# NANO103AE_v1 register map
File version: 1.0
Registers are 32-bit, read-write, reset 0x0 unless marked. A register's access mark holds for its fields unless they carry their own. Offsets are from the block's base; [hi:lo] are bit positions; {n}, {i} and the like mark numbered series.

## DSRC — DSRC Register Map
Base 0x401F0000
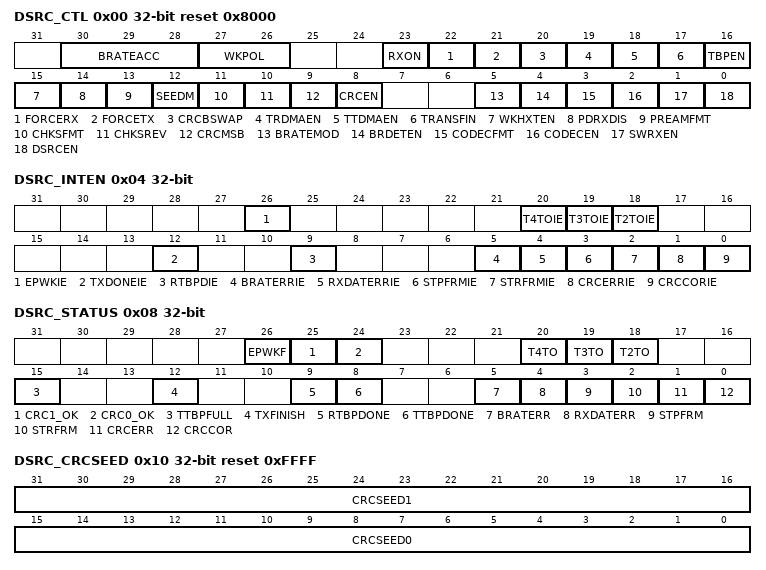
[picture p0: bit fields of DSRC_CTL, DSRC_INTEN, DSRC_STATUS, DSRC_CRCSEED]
0x00 DSRC_CTL reset 0x8000 — DSRC Control Register
  [30:28] BRATEACC — Bit Rate Accuracy Control Bits. Please refer to Table 6.181. Note: This function is only for FM0 CODEC.
  [27:26] WKPOL — Wake-up Pin Polarity Control Bit
    0=Wake-up pin rising edge wake-up DSRC; 1=Wake-up pin falling edge wake-up DSRC
  [23] RXON — RX_ON Control Bit
    0=RX_ON signal Enabled; 1=RX_ON signal Disabled
  [22] FORCERX — Force RX State Control Bit. Note: This bit will be cleared automatically.
    0=No effect; 1=DSRC returns Start_Rx state immediately
  [21] FORCETX — Force TX State Control Bit. Note: This bit will be cleared automatically
    0=No effect; 1=DSRC returns TX state to transmit data immediately
  [20] CRCBSWAP — CRC BYTE SWAP
    0=The received CRC value is not byte swap; 1=The received CRC value is byte swap
  [19] TRDMAEN — TBP Receive DMA Enable Bit
    0=TBP Receiving DMA Disabled; 1=TBP Receiving DMA Enabled
  [18] TTDMAEN — TBP Transmit DMA Enable Bit
    0=TBP Transmitting DMA Disabled; 1=TBP Transmitting DMA Enabled
  [17] TRANSFIN — TBP Transfer Done. When the TTDMAEN (DSRC_CTL[20]) is disabled and the transmitted data is written into DSRC_TX by user, this bit shall be set into the TBP to terminate the processor before the last the transmitted data. The minimum length of transmitted data is 2 bytes. Note: This bit will be cleared after the TTBP transfer is done.
    0=Indicate the TTBP processor is not finished; 1=Inform the TTBP to finish the transparent bit processor after the current byte processed done
  [16] TBPEN — TBP Enable Bit. Setting this bit to 1 enables TBP operation.
    0=TBP function Disabled; 1=TBP function Enabled
  [15] WKHXTEN — Wake-up HXT Clock Enable Bit. Setting this bit to 1 enables RF wake-up HXT clock.
    0=RF wake-up HXT clock Disabled; 1=RF T wake-up HXT clock Enabled
  [14] PDRXDIS — Power-down Mode RXON Disable Bit
    0=RXON signal is always controlled by RXON(DSRC_CTL[23]) bit; 1=RXON signal is disabled during DSRC Power-Down period
  [13] PREAMFMT — Preamble Pattern Format. Note: It is MSB first to be sent.
    0=The preamble length is half word and its pattern is PREPAT (DSRC_PREAMBLE[15:0]); 1=The preamble length is one word and its pattern is PREPAT (DSRC_PREAMBLE[31:0])
  [12] SEEDM — CRC Seed Mode
    0=The transmit CRC seed initial value is CRCSEED0 (DSRC_CRCSEED[15:0]); 1=The transmit CRC seed initial value is CRCSEED1 (DSRC_CRCSEED[31:15])
  [11] CHKSFMT — Checksum Format
    0=No 1's complement for CRC checksum; 1=1's complement for CRC checksum
  [10] CHKSREV — Checksum Reverse. Note: If the checksum data is 0XDD7B0F2E, the bit order reversed for CRC checksum is 0x74F0DEBB.
    0=No bit order reverse for CRC checksum; 1=Bit order reverse for CRC checksum
  [9] CRCMSB — CRC Generation on Data MSB. Note: If the input data is 0xaa, the sequence of CRC bit generation is 01010101 when the bit is set as 0. Otherwise, the sequence of CRC bit generation is 10101010 when the bit is set as 1.
    0=The CRC generation start on the LSB input data first; 1=The CRC generation start on the MSB input data first
  [8] CRCEN — CRC Engine Enable Bit
    0=CRC function Disabled; 1=CRC function Enabled
  [5] BRATEMOD — Bit Rate Error Mode
    0=The DSRC receives the start of frame again; 1=The DSRC does not care the bit rate error message and continue receiving data
  [4] BRDETEN — Bit Rate Detection Enable Bit. Note: This function is only for FM0 CODEC.
    0=Bit rate detection Disabled; 1=Bit rate detection Enabled
  [3] CODECFMT — CODEC Format Select Bit
    0=FM0 CODEC; 1=MONCHESTER CODEC
  [2] CODECEN — CODEC Enable Bit. Note: When both DSRCEN and CODECEN are enabled, the SPI1 will set TXNEG (SPI_CTL[2]), RXNEG (SPI_CTL[1]), CLKPOL (SPI_CTL[11]), SS (SPI_SSCTL[1:0]), SSACTPOL (SPI_SSCTL[2]), AUTOSS (SPI_SSCTL[3]) and SLV3WIRE (SPI_SSCTL[5]) as 0, 1, 0, 0x1, 1, 1, and 1 automatically for FM0 (or Manchester) CODEC communication. In this codition, SPI1 will set the SLAVE (SPI_CTL[18]) bit automatically and operate as Master mode in data transmitting phase and Slave 3-wired mode in data receiving phase automatically.
    0=CODEC Disabled; 1=CODEC Enabled
  [1] SWRXEN — Software Control RX_ON Enable Bit
    0=Software control RX_ON signal Disabled; 1=Software control RX_ON signal Enabled
  [0] DSRCEN — DSRC Enable Bit. Note: When DSRC is enabled, SPI1 will set SUSPITV (SPI_CTL[15:12]), DWIDTH (SPI_CTL[7:3]), REORDER (SPI_CTL[19]), FIFOM (SPI_CTL[21]), TWOBIT (SPI_CTL[22]), and DUALIOEN (SPI_CTL[29]) set as 0x0, 0x8, 0, 1, 0, and 0 automatically for data byte transaction in DSRC application.
    0=DSRC Disabled; 1=DSRC Enabled
0x04 DSRC_INTEN — DSRC Interrupt Enable Register
  [26] EPWKIE — External Pin Wake-up Interrupt Enable Bit
    0=External Pin Wake-up event interrupt Disabled; 1=External Pin Wake-up event interrupt Enabled
  [20] T4TOIE — Timer 4 Time-out Interrupt Enable Bit
    0=T4 Time-out interrupt Disabled; 1=T4 Time-out interrupt Enabled
  [19] T3TOIE — Timer 3 Time-out Interrupt Enable Bit
    0=T3 Time-out interrupt Disabled; 1=T3 Time-out interrupt Enabled
  [18] T2TOIE — Timer 2 Time-out Interrupt Enable Bit
    0=T2 Time-out interrupt Disabled; 1=T2 Time-out interrupt Enabled
  [12] TXDONEIE — Transmit Data Done Interrupt Enable Bit
    0=Transmit data done interrupt Disabled; 1=Transmit data done interrupt Enabled
  [9] RTBPDIE — TBP Byte Receive Done Interrupt Enable Bit
    0=The TBP byte receive done interrupt Disabled; 1=The TBP byte receive done interrupt Enabled
  [5] BRATERRIE — Bit Rate Error Interrupt Enable Bit
    0=Bit Rate Error interrupt Disabled; 1=Bit Rate Error interrupt Enabled
  [4] RXDATERRIE — Received Data Error Interrupt Enable Bit
    0=Received DATA Error interrupt Disabled; 1=Received DATA Rate Error interrupt Enabled
  [3] STPFRMIE — Stop Field of Frame Detection Interrupt Enable Bit
    0=Stop Field of Frame detection Interrupt Disabled; 1=Stop Field of Frame detection Interrupt Enabled
  [2] STRFRMIE — Start Field of Frame Detection Interrupt Enable Bit
    0=Start Field of Frame detection interrupt Disabled; 1=Start Field of Frame detection interrupt Enabled
  [1] CRCERRIE — CRC Error Interrupt Enable Bit
    0=CRC error interrupt Disabled; 1=CRC rate error interrupt Enabled
  [0] CRCCORIE — CRC Check Correct Interrupt Enable Bit
    0=CRC check done without error Interrupt Disabled; 1=CRC check done without error Interrupt Enabled
0x08 DSRC_STATUS
  [26] EPWKF — External Pin Wake-up Event Flag. Note: Write 1 to clear this flag.
    0=No external pin wake-up event happened; 1=External pin wake-up event happened
  [25] CRC1_OK — CRC1 Compare OK. Note: Writing1 to CRCCOR (DSRC_STATUS[0]), CRCERR (DSRC_STATUS[1]) and itself can clear this flag.
    0=The compare result between the receive CRC data and the CHKSUM1 (DSRC_CHKSUM[31:16])is not the same; 1=The compare result between the receive CRC data and the CHKSUM1 (DSRC_CHKSUM[31:16]) is the same
  [24] CRC0_OK — CRC0 Compare OK. Note: Writing1 to CRCCOR (DSRC_STATUS[0]), CRCERR (DSRC_STATUS[1]) and itself can clear this flag.
    0=The compare result between the receive CRC data and the CHKSUM0 (DSRC_CHKSUM[15:0])is not the same; 1=The compare result between the receive CRC data and the CHKSUM0 (DSRC_CHKSUM[15:0]) is the same
  [20] T4TO — Timer 4 Time-out Flag. This flag is set after the Timer Controller finishes counting the value set by DSRC_TMR4. Note1: The Timer Counter is started when SPI detected the Stop of Frame and DSRC CRC correct flag is active. Note2: Write 1 to clear this flag.
  [19] T3TO — Timer 3 Time-out Flag. This flag is set after the Timer Controller finishes counting the value set by DSRC_TMR3. Note1: The Timer Counter is startedwhen the Start of Frame is detected and the counter is cleared when the Stop of Frame is detect before the T3TO event is set. Note2: Write 1 to clear this flag.
  [18] T2TO — Timer 2 Time-out Flag. This flag is set after the Timer Controller finishes counting the value set by DSRC_TMR2. Note1: The Timer Counter is started when DSRC wake-up and the counter is cleared when the Start of Frame is detected before T2TO event is set. Note2: Write 1 to clear this flag.
  [15] TTBPFULL — TTBPTransmit Full. Note: If the TTDMAEN (DSRC_CTL[18] is disabled, the transmitted data can be written into the DSRC_TX register when the TTBPDONE (DSRC_STATUS[8]) is set to 1 and the TTBPFULL must be set as 0. Otherwise, the TTBP transmit done flag TTBPDONE (DSRC_STATUS[8]) won't be active in next data.
    0=TBP TX Transmit is not full; 1=TBP TX Transmit is full
  [12] TXFINISH — TX Transfer Finish. Note:Write 1 to clear this flag.
    0=The TX transfer is not finished; 1=All the data processed by the TTBP block and the CRC, trail 7E patterns had been transmitted finish by SPI interface
  [9] RTBPDONE — TBP Byte Receive Done. Note: This bit is automatically cleared by TBP_RXDMA_ACK when the TRDMAEN (DSRC_CTL[19]) is set or by the read signal of DSRC_RX register when the TRDMAEN (DSRC_CTL[19]) is not set.
    0=The TBP byte receive is not finished; 1=The TBP byte receive has done
  [8] TTBPDONE — TBP Byte Transfer Done. Note 1: This bit is automatically cleared by TBP_TXDMA_ACK when the TTDMAEN (DSRC_CTL[18]) is set or by the write signal of DSRC_TX register when the TTDMAEN (DSRC_CTL[18]) is not set. Note 2: If the TTDMAEN (DSRC_CTL[18]) is not set, the first TTBPDONE is set after the TTBP module send out the PREAMBLE and Head 7E patterns. The first transmitted data shall be written into the TX (DSRC_TX) after this flag is set. Note 3: After the TRANFIN (DSRC_CTL[17]) is set, this bit won't report the byte transfer done status again. The user shall check the TXDONE (DSRC_STATUS[12]) to know the current transfer has done both on the TTBP and SPI device.
    0=The TBP byte transfer is not finished; 1=The TBP byte transfer has been finished
  [5] BRATERR — Bit Rate Error Flag. This flag indicates FM0 or MANCHESTER bit rate error depending on CODECFMT (DSRC_CTL[3]) setting if BRDETEN (DSRC_CTL[4]) is set to 1. Note: Write 1 to clear this flag.
  [4] RXDATERR — Received Data Error Flag. Note: Write 1 to clear this flag.
    0=The received data packet error happened; 1=The received data packet has successive 7 bit 1. It indicates the receive frame shall be thrown out
  [3] STPFRM — Stop Field of Frame Detection Flag. This flag indicates stop field of frame is detected. Note: Write 1 to clear this flag.
  [2] STRFRM — Start Field of Frame Detection Flag. This flag indicates start field of frame is detected. Note: Write 1 to clear this flag.
  [1] CRCERR — CRC Error Bit
    0=This flag indicates CRC check done and result is correct; 1=If the CRC function is enabled (CRCEN(DSRC_CTL[8])=1,this flag indicates CRC check done and result is error on CHKSUM0 (DSRC_CHKSUM[15:0]) and CHKSUM1 (DSRC_CHKSUM[31:16]), else writ 1 to this bit to indicate that MCU CRC check error
  [0] CRCCOR — CRC CorrectBit
    0=This flag indicates CRC check done and result is not correct on CHKSUM0 (DSRC_CHKSUM[15:0]) and CHKSUM1 (DSRC_CHKSUM[31:16]); 1=If the CRC function is enabled (CRCEN(DSRC_CTL[8])=1, this flag indicates CRC check done and result is correct on CHKSUM0 (DSRC_CHKSUM[15:0]) or CHKSUM1 (DSRC_CHKSUM[31:16]), else writ 1 to this bit to indicate that MCU CRC check correct
0x0C DSRC_PREAMBLE — DSRC Preamble Pattern Register
  [31:0] PREPAT — The Preamble Pattern. The bit field indicates the preamble pattern of DSRC. If the PREAMFMT (DSRC_CTL[24]) is set to 1, 32-bit preamble pattern is transmitted and the transmitted sequence is PREPAT[31:24], PREPAT[23:16], PREPAT[15:8] and PREPAT[7:0]. If the PREAMFMT (DSRC_CTL[24]) is set to 0, 16-bit preamble pattern is transmitted and the transmitted sequence is PREPAT[15:8] and PREPAT[7:0].
0x10 DSRC_CRCSEED reset 0xFFFF — DSRC CRC Seed Initial Register
  [31:16] CRCSEED1 — The CRC Seed Initial Pattern 1. The bit field indicates the CRC seed initial pattern 1 of DSRC. For receiver: The CRC will be calculated by the initial value. The TBP will auto compare the calculated result with the received CRC data and report its compare result into CRC1_OK (DSRC_STATUAS[25]). For transmitter: The bit field is used to generate the CRC when the SEEDM (DSRC_CTL[20]) is set to 1.
  [15:0] CRCSEED0 — The CRC Seed Initial Pattern 0. The bits field indicates the CRC seed initial pattern 0 of DSRC. For receiver: The CRC will be calculated by the initial value. The TBP will auto compare the calculated result with the received CRC data and report its compare result into CRC0_OK (DSRC_STATUAS[24]). For Transmit: The bit field is used to generate the CRC when the SEEDM (DSRC_CTL[20]) is set to 0.
0x14 DSRC_RBCNT ro — DSRC Receive Byte Count Register
  [8:0] TBPBCNT — TBP Receive Byte Count. The bits field indicates the number of receive byte count on RTBP when the CRCCOR (DSRC_STATUS[0]) is set to 1 and the STPFRM(DSRC_STATUS[3]) is set to 1. Otherwise, the value is 0. Note 1: The 2 bytes CRC is not calculated in this field. Note 2: If there is CRC calculation check error, the value will be cleared by hardware to calculate the next incoming data stream.
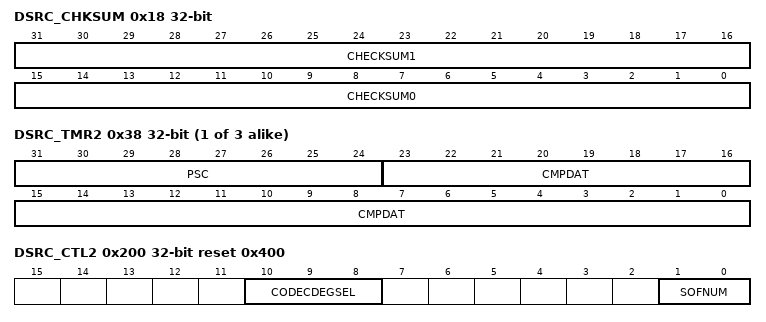
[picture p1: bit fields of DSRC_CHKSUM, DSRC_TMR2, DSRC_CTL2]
0x18 DSRC_CHKSUM ro — DSRC Checksum Register
  [31:16] CHECKSUM1 — The CRC Checksum1. The bit field indicates the CRC checksum of the initial value is CHKSUM1 (DSRC_CHKSUM[31:16])
  [15:0] CHECKSUM0 — The CRC Checksum0. The bit field indicates the CRC checksum of the initial value is CHKSUM0 (DSRC_CHKSUM[15:0]).
0x20 DSRC_TX wo — DSRC TX Data Register
  [7:0] TX — TBP Transmit Data. The bit field indicates the transmitted data on the TBP before being transmitted to TTBP.
0x24 DSRC_RX ro — DSRC RX Data Register
  [7:0] RX — TBP Receiver Data. The bit field indicates the received data on the TBP after the RTBP.
{0x30+4i} DSRC_TMR{i} (i=2..4) — DSRC Timer {i} Register
  [31:24] PSC — Prescale Counter
  [23:0] CMPDAT — Timer Compared Value. CMPDAT is a 24-bit compared value register. When the internal 24-bit up counter value is equal to CMPDAT value, the CNTIF (TIMERx_INTSTS[0] Timer Interrupt Flag) will be set to 1. Note1: Never write 0x0 or 0x1 in CMPDAT, or the core will run into unknown state.
0x200 DSRC_CTL2 reset 0x400 — DSRC Control Register 2
  [10:8] CODECDEGSEL — FM0 CODEC Deglitch Selection. This bits field is used to define how much width of glitch would be filtered.
    0=disable to the CODECdeglitch selection; 1=Filter the glitches that the width is 0.25us or less; 2=Filter the glitches that the width is 0.50us or less; 3=Filter the glitches that the width is 0.75us or less; 4=Filter the glitches that the width is 1.00us or less; 5=Filter the glitches that the width is 1.25us or less
  [1:0] SOFNUM — Start of Frame Number for Transmission. This bit field is used to define the number of SOF packet which is repeated send in the SPI bus before the transmitted data.
    0=1 Start field of frame after the Preamble; 1=2Start field of frame after the Preamble; 2=3Start field of framesafter the Preamble; 3=4 Start field of frames after the Preamble
0x210 DSRC_TXR ro — DSRC Transmit Data After TTBP Register
  [7:0] TXDATR — Transmit Data After TTBP. The bits field indicates the transmitted data after the TTBP. When the 8-Bit transmitted data is processed by the TTBP, the register indicates the processed content.
0x214 DSRC_RXR ro — DSRC Receive Data Before RTBP Register
  [7:0] RXDATR — Receive Data Before RTBP. The bits field indicates the current receive data before the RTBP (It comes from the SPI RX buffer). Before the 8-Bit is processed by the RTBP, the register indicates the un-processed content.
0x218 DSRC_ICR ro — DSRC Internal Use Control Register
